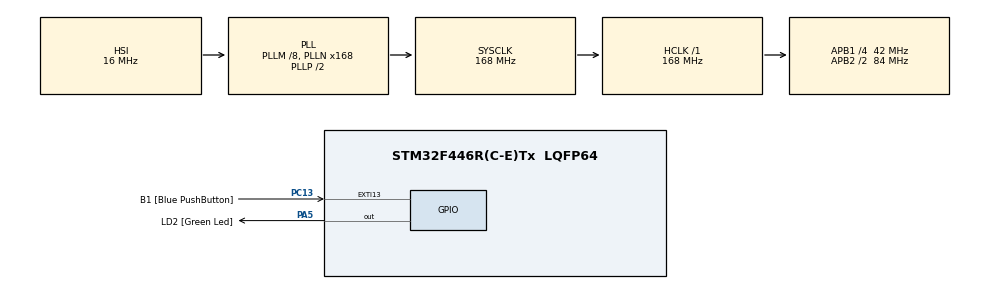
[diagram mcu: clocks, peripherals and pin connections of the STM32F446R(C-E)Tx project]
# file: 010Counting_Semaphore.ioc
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Mcu.Family=STM32F4
Mcu.Name=STM32F446R(C-E)Tx
Mcu.Package=LQFP64
NVIC.EXTI15_10_IRQn=true\:6\:0\:true\:false\:true\:true\:true\:true
NVIC.PriorityGroup=NVIC_PRIORITYGROUP_4
NVIC.TimeBase=TIM6_DAC_IRQn
NVIC.TimeBaseIP=TIM6
PA13.GPIO_Label=TMS
PA13.Signal=SYS_JTMS-SWDIO
PA14.GPIO_Label=TCK
PA14.Signal=SYS_JTCK-SWCLK
PA2.GPIO_Label=USART_TX
PA2.Signal=USART2_TX
PA3.GPIO_Label=USART_RX
PA3.Signal=USART2_RX
PA5.GPIO_Label=LD2 [Green Led]
PA5.Signal=GPIO_Output
PB3.GPIO_Label=SWO
PB3.Signal=SYS_JTDO-SWO
PC13.GPIO_Label=B1 [Blue PushButton]
PC13.GPIO_ModeDefaultEXTI=GPIO_MODE_IT_FALLING
PC13.Signal=GPXTI13
PC14-OSC32_IN.Signal=RCC_OSC32_IN
PC15-OSC32_OUT.Signal=RCC_OSC32_OUT
PH0-OSC_IN.Signal=RCC_OSC_IN
PH1-OSC_OUT.Signal=RCC_OSC_OUT
ProjectManager.HeapSize=0x200
ProjectManager.StackSize=0x400
ProjectManager.TargetToolchain=STM32CubeIDE
RCC.AHBFreq_Value=168000000
RCC.APB1CLKDivider=RCC_HCLK_DIV4
RCC.APB1Freq_Value=42000000
RCC.APB1TimFreq_Value=84000000
RCC.APB2CLKDivider=RCC_HCLK_DIV2
RCC.APB2Freq_Value=84000000
RCC.APB2TimFreq_Value=168000000
RCC.CortexFreq_Value=168000000
RCC.FLatency-AdvancedSettings=FLASH_LATENCY_5
RCC.HCLKFreq_Value=168000000
RCC.HSE_VALUE=8000000
RCC.HSI_VALUE=16000000
RCC.LSE_VALUE=32768
RCC.PLLM=8
RCC.PLLN=168
RCC.SYSCLKFreq_VALUE=168000000
RCC.SYSCLKSource=RCC_SYSCLKSOURCE_PLLCLK
RCC.USBFreq_Value=168000000
RCC.VCOOutputFreq_Value=336000000
VP_SYS_VS_tim6.Mode=TIM6
board=NUCLEO-F446RE

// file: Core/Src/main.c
/* USER CODE BEGIN Header */
/**
  ******************************************************************************
  * @file           : main.c
  * @brief          : Main program body
  ******************************************************************************
  * @attention
  *
  * Copyright (c) 2026 STMicroelectronics.
  * All rights reserved.
  *
  * This software is licensed under terms that can be found in the LICENSE file
  * in the root directory of this software component.
  * If no LICENSE file comes with this software, it is provided AS-IS.
  *
  ******************************************************************************
  */
/* USER CODE END Header */
#include "main.h"

/* USER CODE BEGIN Includes */
#include "FreeRTOS.h"
#include "task.h"
#include "semphr.h"
#include "queue.h"
#include "stm32f4xx.h"

#include <stdio.h>
#include <stdlib.h>
#include<stdint.h>
#include <string.h>
/* USER CODE END Includes */

/* USER CODE BEGIN PV */

#define DWT_CTRL    (*(volatile uint32_t*)0xE0001000)

/* USER CODE END PV */

void SystemClock_Config(void);
static void MX_GPIO_Init(void);
/* USER CODE BEGIN PFP */
char usr_msg[250]={0};

TaskHandle_t xTaskHandle1=NULL;
TaskHandle_t xTaskHandle2=NULL;

void printmsg(char *msg);

/* The tasks to be created. */
static void vHandlerTask( void *pvParameters );
static void vPeriodicTask( void *pvParameters );

static void prvSetupSoftwareInterrupt(void);

extern void SEGGER_UART_init(uint32_t);

xSemaphoreHandle xCountingSemaphore;
/* USER CODE END PFP */

int main(void)
{

  /* MCU Configuration--------------------------------------------------------*/

  /* Reset of all peripherals, Initializes the Flash interface and the Systick. */
  HAL_Init();

  /* Configure the system clock */
  SystemClock_Config();

  /* Initialize all configured peripherals */
  MX_GPIO_Init();
  /* USER CODE BEGIN 2 */
  //this is here to collect segger event time stamp
  	DWT->CTRL |= (1 << 0);//Enable CYCCNT in DWT_CTRL.

  	//Start Recording
  	SEGGER_SYSVIEW_Conf();
  	SEGGER_SYSVIEW_Start();

  	sprintf(usr_msg,"Demo of usage of counting semaphore\r\n");
  		printmsg(usr_msg);

  	    /* Before a semaphore is used it must be explicitly created.  In this example
  		a counting semaphore is created.  The semaphore is created to have a maximum
  		count value of 10, and an initial count value of 0. */
  	    xCountingSemaphore = xSemaphoreCreateCounting( 10, 0 );

  		/* Check the semaphore was created successfully. */
  		if( xCountingSemaphore != NULL )
  		{
  	    	/* Enable the button interrupt and set its priority. */
  	    	prvSetupSoftwareInterrupt();

  			/* Create the 'handler' task.  This is the task that will be synchronized
  			with the interrupt.  The handler task is created with a high priority to
  			ensure it runs immediately after the interrupt exits.  In this case a
  			priority of 3 is chosen. */
  			xTaskCreate( vHandlerTask, "Handler", 500, NULL, 1, NULL );

  			/* Create the task that will periodically generate a software interrupt.
  			This is created with a priority below the handler task to ensure it will
  			get preempted each time the handler task exist the Blocked state. */
  			xTaskCreate( vPeriodicTask, "Periodic", 500, NULL, 3, NULL );

  			/* Start the scheduler so the created tasks start executing. */
  			vTaskStartScheduler();
  		}

  	    /* If all is well we will never reach here as the scheduler will now be
  	    running the tasks.  If we do reach here then it is likely that there was
  	    insufficient heap memory available for a resource to be created. */
  		for( ;; );
  	}
  	/*-----------------------------------------------------------*/

  	static void vHandlerTask( void *pvParameters )
  	{
  		/* As per most tasks, this task is implemented within an infinite loop. */
  		for( ;; )
  		{
  			/* Use the semaphore to wait for the event.  The semaphore was created
  			before the scheduler was started so before this task ran for the first
  			time.  The task blocks indefinitely meaning this function call will only
  			return once the semaphore has been successfully obtained - so there is no
  			need to check the returned value. */
  			xSemaphoreTake( xCountingSemaphore, portMAX_DELAY );

  			/* To get here the event must have occurred.  Process the event (in this
  			case we just print out a message). */
  			sprintf(usr_msg, "Handler task - Processing event.\r\n");
  			printmsg(usr_msg);
  		}
  	}
  	/*-----------------------------------------------------------*/

  	static void vPeriodicTask( void *pvParameters )
  	{
  		/* As per most tasks, this task is implemented within an infinite loop. */
  		for( ;; )
  		{
  			/* This task is just used to 'simulate' an interrupt.  This is done by
  			periodically generating a software interrupt. */
  			vTaskDelay( pdMS_TO_TICKS(500) );

  			/* Generate the interrupt, printing a message both before hand and
  			afterwards so the sequence of execution is evident from the output. */
  	        sprintf(usr_msg, "Periodic task - Pending the interrupt.\r\n" );
  	    	printmsg(usr_msg);

  	        //pend the interrupt
  	        NVIC_SetPendingIRQ(EXTI15_10_IRQn);

  	        sprintf(usr_msg, "Periodic task - Resuming.\r\n" );
  	        printmsg(usr_msg);

  		}
  	}
  	/*-----------------------------------------------------------*/

  	static void prvSetupSoftwareInterrupt(void)
  	{
  		/* here were simulating the button interrupt by manually setting the interrupt enable bit in the NVIC enable register*/

  		/* The interrupt service routine uses an (interrupt safe) FreeRTOS API
  		function so the interrupt priority must be at or below the priority defined
  		by configSYSCALL_INTERRUPT_PRIORITY. */

  		NVIC_SetPriority( EXTI15_10_IRQn, configLIBRARY_MAX_SYSCALL_INTERRUPT_PRIORITY );

  		/* Enable the interrupt. */
  		NVIC_EnableIRQ( EXTI15_10_IRQn );
  	}
  	/*-----------------------------------------------------------*/
  	void EXTI15_10_IRQHandler( void )
  	{
  		portBASE_TYPE xHigherPriorityTaskWoken = pdFALSE;

  		/* 'Give' the semaphore multiple times.  The first will unblock the handler
  		task, the following 'gives' are to demonstrate that the semaphore latches
  		the events to allow the handler task to process them in turn without any
  		events getting lost.  This simulates multiple interrupts being taken by the
  		processor, even though in this case the events are simulated within a single
  		interrupt occurrence.*/
  		sprintf(usr_msg,"==>Button_Handler\r\n");
  		printmsg(usr_msg);

  		xSemaphoreGiveFromISR( xCountingSemaphore, &xHigherPriorityTaskWoken );
  		xSemaphoreGiveFromISR( xCountingSemaphore, &xHigherPriorityTaskWoken );
  		xSemaphoreGiveFromISR( xCountingSemaphore, &xHigherPriorityTaskWoken );
  		xSemaphoreGiveFromISR( xCountingSemaphore, &xHigherPriorityTaskWoken );
  		xSemaphoreGiveFromISR( xCountingSemaphore, &xHigherPriorityTaskWoken );

  	    /* Clear the software interrupt bit using the interrupt controllers  */

  	    /* Giving the semaphore may have unblocked a task - if it did and the
  	    unblocked task has a priority equal to or above the currently executing
  	    task then xHigherPriorityTaskWoken will have been set to pdTRUE and
  	    portEND_SWITCHING_ISR() will force a context switch to the newly unblocked
  	    higher priority task.

  	    NOTE: The syntax for forcing a context switch within an ISR varies between
  	    FreeRTOS ports.  The portEND_SWITCHING_ISR() macro is provided as part of
  	    the Cortex M3 port layer for this purpose.  taskYIELD() must never be called
  	    from an ISR! */
  	    portEND_SWITCHING_ISR( xHigherPriorityTaskWoken );
  	}
  	/*-----------------------------------------------------------*/

  /* USER CODE END 2 */

void SystemClock_Config(void)
{
  RCC_OscInitTypeDef RCC_OscInitStruct = {0};
  RCC_ClkInitTypeDef RCC_ClkInitStruct = {0};

  /** Configure the main internal regulator output voltage
  */
  __HAL_RCC_PWR_CLK_ENABLE();
  __HAL_PWR_VOLTAGESCALING_CONFIG(PWR_REGULATOR_VOLTAGE_SCALE1);

  /** Initializes the RCC Oscillators according to the specified parameters
  * in the RCC_OscInitTypeDef structure.
  */
  RCC_OscInitStruct.OscillatorType = RCC_OSCILLATORTYPE_HSI;
  RCC_OscInitStruct.HSIState = RCC_HSI_ON;
  RCC_OscInitStruct.HSICalibrationValue = RCC_HSICALIBRATION_DEFAULT;
  RCC_OscInitStruct.PLL.PLLState = RCC_PLL_ON;
  RCC_OscInitStruct.PLL.PLLSource = RCC_PLLSOURCE_HSI;
  RCC_OscInitStruct.PLL.PLLM = 8;
  RCC_OscInitStruct.PLL.PLLN = 168;
  RCC_OscInitStruct.PLL.PLLP = RCC_PLLP_DIV2;
  RCC_OscInitStruct.PLL.PLLQ = 2;
  RCC_OscInitStruct.PLL.PLLR = 2;
  if (HAL_RCC_OscConfig(&RCC_OscInitStruct) != HAL_OK)
  {
    Error_Handler();
  }

  /** Initializes the CPU, AHB and APB buses clocks
  */
  RCC_ClkInitStruct.ClockType = RCC_CLOCKTYPE_HCLK|RCC_CLOCKTYPE_SYSCLK
                              |RCC_CLOCKTYPE_PCLK1|RCC_CLOCKTYPE_PCLK2;
  RCC_ClkInitStruct.SYSCLKSource = RCC_SYSCLKSOURCE_PLLCLK;
  RCC_ClkInitStruct.AHBCLKDivider = RCC_SYSCLK_DIV1;
  RCC_ClkInitStruct.APB1CLKDivider = RCC_HCLK_DIV4;
  RCC_ClkInitStruct.APB2CLKDivider = RCC_HCLK_DIV2;

  if (HAL_RCC_ClockConfig(&RCC_ClkInitStruct, FLASH_LATENCY_5) != HAL_OK)
  {
    Error_Handler();
  }
}

static void MX_GPIO_Init(void)
{
  GPIO_InitTypeDef GPIO_InitStruct = {0};

  /* GPIO Ports Clock Enable */
  __HAL_RCC_GPIOC_CLK_ENABLE();
  __HAL_RCC_GPIOH_CLK_ENABLE();
  __HAL_RCC_GPIOA_CLK_ENABLE();
  __HAL_RCC_GPIOB_CLK_ENABLE();

  /*Configure GPIO pin Output Level */
  HAL_GPIO_WritePin(LD2_GPIO_Port, LD2_Pin, GPIO_PIN_RESET);

  /*Configure GPIO pin : B1_Pin */
  GPIO_InitStruct.Pin = B1_Pin;
  GPIO_InitStruct.Mode = GPIO_MODE_IT_FALLING;
  GPIO_InitStruct.Pull = GPIO_NOPULL;
  HAL_GPIO_Init(B1_GPIO_Port, &GPIO_InitStruct);

  /*Configure GPIO pins : USART_TX_Pin USART_RX_Pin */
  GPIO_InitStruct.Pin = USART_TX_Pin|USART_RX_Pin;
  GPIO_InitStruct.Mode = GPIO_MODE_AF_PP;
  GPIO_InitStruct.Pull = GPIO_NOPULL;
  GPIO_InitStruct.Speed = GPIO_SPEED_FREQ_VERY_HIGH;
  GPIO_InitStruct.Alternate = GPIO_AF7_USART2;
  HAL_GPIO_Init(GPIOA, &GPIO_InitStruct);

  /*Configure GPIO pin : LD2_Pin */
  GPIO_InitStruct.Pin = LD2_Pin;
  GPIO_InitStruct.Mode = GPIO_MODE_OUTPUT_PP;
  GPIO_InitStruct.Pull = GPIO_NOPULL;
  GPIO_InitStruct.Speed = GPIO_SPEED_FREQ_LOW;
  HAL_GPIO_Init(LD2_GPIO_Port, &GPIO_InitStruct);

  /* EXTI interrupt init*/
  HAL_NVIC_SetPriority(EXTI15_10_IRQn, 6, 0);
  HAL_NVIC_EnableIRQ(EXTI15_10_IRQn);

}

/* USER CODE BEGIN 4 */
void printmsg(char *msg)
{
    SEGGER_SYSVIEW_PrintfTarget("%s", msg);
}
/* USER CODE END 4 */

void HAL_TIM_PeriodElapsedCallback(TIM_HandleTypeDef *htim)
{
  if (htim->Instance == TIM6)
  {
    HAL_IncTick();
  }
}

void Error_Handler(void)
{
  __disable_irq();
  while (1)
  {
  }
}
